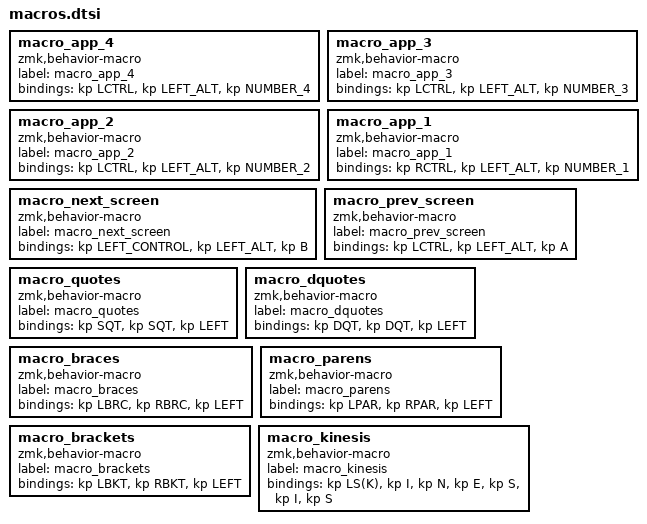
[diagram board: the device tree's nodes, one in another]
macro_app_4: macro_app_4{
compatible = "zmk,behavior-macro";
label = "macro_app_4";
#binding-cells = <0>;
bindings = <&kp LCTRL>, <&kp LEFT_ALT>, <&kp NUMBER_4>;
};
macro_app_3: macro_app_3{
compatible = "zmk,behavior-macro";
label = "macro_app_3";
#binding-cells = <0>;
bindings = <&kp LCTRL>, <&kp LEFT_ALT>, <&kp NUMBER_3>;
};
macro_app_2: macro_app_2{
compatible = "zmk,behavior-macro";
label = "macro_app_2";
#binding-cells = <0>;
bindings = <&kp LCTRL>, <&kp LEFT_ALT>, <&kp NUMBER_2>;
};
macro_app_1: macro_app_1{
compatible = "zmk,behavior-macro";
label = "macro_app_1";
#binding-cells = <0>;
bindings = <&kp RCTRL>, <&kp LEFT_ALT>, <&kp NUMBER_1>;
};
macro_next_screen: macro_next_screen{
compatible = "zmk,behavior-macro";
label = "macro_next_screen";
#binding-cells = <0>;
bindings = <&kp LEFT_CONTROL>, <&kp LEFT_ALT>, <&kp B>;
};
macro_prev_screen: macro_prev_screen{
compatible = "zmk,behavior-macro";
label = "macro_prev_screen";
#binding-cells = <0>;
bindings = <&kp LCTRL>, <&kp LEFT_ALT>, <&kp A>;
};
macro_quotes: macro_quotes{
compatible = "zmk,behavior-macro";
label = "macro_quotes";
#binding-cells = <0>;
bindings = <&kp SQT>, <&kp SQT>, <&kp LEFT>;
};
macro_dquotes: macro_dquotes{
compatible = "zmk,behavior-macro";
label = "macro_dquotes";
#binding-cells = <0>;
bindings = <&kp DQT>, <&kp DQT>, <&kp LEFT>;
};
macro_braces: macro_braces{
compatible = "zmk,behavior-macro";
label = "macro_braces";
#binding-cells = <0>;
bindings = <&kp LBRC>, <&kp RBRC>, <&kp LEFT>;
};
macro_parens: macro_parens{
compatible = "zmk,behavior-macro";
label = "macro_parens";
#binding-cells = <0>;
bindings = <&kp LPAR>, <&kp RPAR>, <&kp LEFT>;
};
macro_brackets: macro_brackets{
compatible = "zmk,behavior-macro";
label = "macro_brackets";
#binding-cells = <0>;
bindings = <&kp LBKT>, <&kp RBKT>, <&kp LEFT>;
};
macro_kinesis: macro_kinesis{
compatible = "zmk,behavior-macro";
label = "macro_kinesis";
#binding-cells = <0>;
bindings = <&kp LS(K)>, <&kp I>, <&kp N>, <&kp E>, <&kp S>, <&kp I>, <&kp S>;
};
